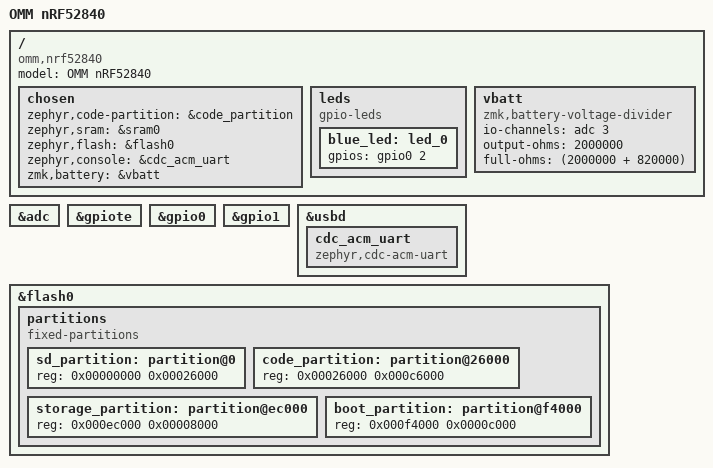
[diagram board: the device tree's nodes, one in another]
/dts-v1/;
#include <nordic/nrf52840_qiaa.dtsi>

/ {
    model = "OMM nRF52840";
    compatible = "omm,nrf52840";

    chosen {
        zephyr,code-partition = &code_partition;
        zephyr,sram = &sram0;
        zephyr,flash = &flash0;
        zephyr,console = &cdc_acm_uart;
        zmk,battery = &vbatt;
    };

    leds {
        compatible = "gpio-leds";
        blue_led: led_0 {
            gpios = <&gpio0 2 GPIO_ACTIVE_HIGH>;
        };
    };

    vbatt: vbatt {
        compatible = "zmk,battery-voltage-divider";
        io-channels = <&adc 3>;
        output-ohms = <2000000>;
        full-ohms = <(2000000 + 820000)>;
    };
};

&adc {
    status = "okay";
};

&gpiote {
    status = "okay";
};

&gpio0 {
    status = "okay";
};

&gpio1 {
    status = "okay";
};

&usbd {
    status = "okay";
    cdc_acm_uart: cdc_acm_uart {
        compatible = "zephyr,cdc-acm-uart";
    };
};

&flash0 {
    partitions {
        compatible = "fixed-partitions";
        #address-cells = <1>;
        #size-cells = <1>;

        sd_partition: partition@0 {
            reg = <0x00000000 0x00026000>;
        };
        code_partition: partition@26000 {
            reg = <0x00026000 0x000c6000>;
        };
        storage_partition: partition@ec000 {
            reg = <0x000ec000 0x00008000>;
        };
        boot_partition: partition@f4000 {
            reg = <0x000f4000 0x0000c000>;
        };
    };
};
